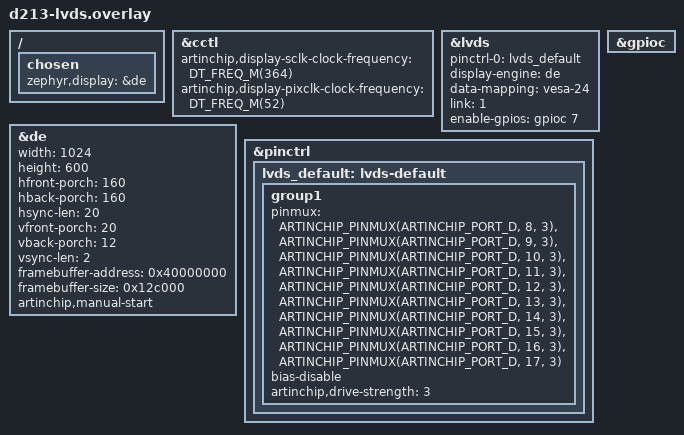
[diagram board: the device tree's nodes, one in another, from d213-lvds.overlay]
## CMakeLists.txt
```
# SPDX-FileCopyrightText: Copyright (c) 2026 UltraSemi
# SPDX-License-Identifier: Apache-2.0
cmake_minimum_required(VERSION 3.20.0)
find_package(Zephyr REQUIRED HINTS $ENV{ZEPHYR_BASE})
project(boot_shell)
target_sources(app PRIVATE src/main.c)
target_sources_ifdef(CONFIG_DISPLAY app PRIVATE src/display_test.c)
```

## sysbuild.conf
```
# SPDX-FileCopyrightText: Copyright (c) 2026 UltraSemi
# SPDX-License-Identifier: Apache-2.0
SB_CONFIG_BOOTLOADER_MCUBOOT=y
SB_CONFIG_MCUBOOT_MODE_RAM_LOAD=y
SB_CONFIG_BOOT_SIGNATURE_TYPE_ECDSA_P256=y
```

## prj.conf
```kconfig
# SPDX-FileCopyrightText: Copyright (c) 2026 UltraSemi
# SPDX-License-Identifier: Apache-2.0
CONFIG_SERIAL=y
CONFIG_CONSOLE=y
CONFIG_UART_CONSOLE=y
CONFIG_SHELL=y
CONFIG_SHELL_BACKEND_SERIAL=y
CONFIG_SHELL_BACKEND_SERIAL_INTERRUPT_DRIVEN=n
CONFIG_SHELL_BACKEND_SERIAL_API_POLLING=y
CONFIG_SHELL_BACKEND_SERIAL_RX_POLL_PERIOD=2
CONFIG_SHELL_BACKEND_SERIAL_RX_RING_BUFFER_SIZE=256
CONFIG_SHELL_PROMPT_UART="aic:~$ "
CONFIG_LOG=y
CONFIG_LOG_BACKEND_UART=n
CONFIG_SHELL_LOG_BACKEND=y
CONFIG_BOOT_BANNER=n
CONFIG_MAIN_STACK_SIZE=2048
```

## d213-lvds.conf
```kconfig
# SPDX-FileCopyrightText: Copyright (c) 2026 UltraSemi
# SPDX-License-Identifier: Apache-2.0
CONFIG_DISPLAY=y
CONFIG_GPIO=y
CONFIG_MAIN_STACK_SIZE=4096
CONFIG_MAIN_THREAD_PRIORITY=5
```

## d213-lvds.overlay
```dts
/*
 * SPDX-FileCopyrightText: Copyright (c) 2026 UltraSemi Technology Development Co., Ltd.
 * SPDX-License-Identifier: Apache-2.0
 *
 * D213 demo128 NAND: LubanLite origin/master f2ee295b1a09 LVDS defaults.
 */

#include <zephyr/dt-bindings/gpio/gpio.h>
#include <zephyr/dt-bindings/pinctrl/artinchip-pinctrl.h>

/ {
	chosen {
		zephyr,display = &de;
	};
};

&cctl {
	artinchip,display-sclk-clock-frequency = <DT_FREQ_M(364)>;
	artinchip,display-pixclk-clock-frequency = <DT_FREQ_M(52)>;
};

&lvds {
	pinctrl-0 = <&lvds_default>;
	pinctrl-names = "default";
	display-engine = <&de>;
	data-mapping = "vesa-24";
	link = <1>;
	enable-gpios = <&gpioc 7 GPIO_ACTIVE_HIGH>;
	status = "okay";
};

&de {
	width = <1024>;
	height = <600>;
	hfront-porch = <160>;
	hback-porch = <160>;
	hsync-len = <20>;
	vfront-porch = <20>;
	vback-porch = <12>;
	vsync-len = <2>;
	framebuffer-address = <0x40000000>;
	framebuffer-size = <0x12c000>;
	status = "okay";
	artinchip,manual-start;
};

&pinctrl {
	lvds_default: lvds-default {
		group1 {
			pinmux = <ARTINCHIP_PINMUX(ARTINCHIP_PORT_D, 8, 3)>,
				 <ARTINCHIP_PINMUX(ARTINCHIP_PORT_D, 9, 3)>,
				 <ARTINCHIP_PINMUX(ARTINCHIP_PORT_D, 10, 3)>,
				 <ARTINCHIP_PINMUX(ARTINCHIP_PORT_D, 11, 3)>,
				 <ARTINCHIP_PINMUX(ARTINCHIP_PORT_D, 12, 3)>,
				 <ARTINCHIP_PINMUX(ARTINCHIP_PORT_D, 13, 3)>,
				 <ARTINCHIP_PINMUX(ARTINCHIP_PORT_D, 14, 3)>,
				 <ARTINCHIP_PINMUX(ARTINCHIP_PORT_D, 15, 3)>,
				 <ARTINCHIP_PINMUX(ARTINCHIP_PORT_D, 16, 3)>,
				 <ARTINCHIP_PINMUX(ARTINCHIP_PORT_D, 17, 3)>;
			bias-disable;
			artinchip,drive-strength = <3>;
		};
	};
};

&gpioc {
	status = "okay";
};
```

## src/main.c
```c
/*
 * SPDX-FileCopyrightText: Copyright (c) 2026 UltraSemi
 * SPDX-License-Identifier: Apache-2.0
 */
#include <zephyr/kernel.h>
#include <zephyr/logging/log.h>

LOG_MODULE_REGISTER(boot_shell, LOG_LEVEL_INF);

#ifdef CONFIG_DISPLAY
int boot_display_test(void);
#endif

int main(void)
{
	LOG_INF("Zephyr boot test: %s", CONFIG_BOARD_TARGET);
#ifdef CONFIG_DISPLAY
	return boot_display_test();
#else
	LOG_INF("Type help to test the shell; display is not enabled in this image");
#endif
	return 0;
}
```

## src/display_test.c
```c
/*
 * SPDX-FileCopyrightText: Copyright (c) 2026 UltraSemi
 * SPDX-License-Identifier: Apache-2.0
 */
#include <zephyr/device.h>
#include <zephyr/drivers/display.h>
#include <zephyr/kernel.h>
#include <zephyr/logging/log.h>

LOG_MODULE_REGISTER(display_test, LOG_LEVEL_INF);

static uint16_t row[1024];
static const uint16_t colors[] = {0xffff, 0xffe0, 0x07ff, 0x07e0,
				0xf81f, 0xf800, 0x001f, 0x0000};

int boot_display_test(void)
{
	const struct device *display = DEVICE_DT_GET(DT_CHOSEN(zephyr_display));
	struct display_capabilities caps;
	struct display_buffer_descriptor desc = {0};
	uint16_t marker = 0;
	int ret;

	if (!device_is_ready(display)) {
		LOG_ERR("Display is not ready; shell remains available");
		return -ENODEV;
	}
	display_get_capabilities(display, &caps);
	if (caps.x_resolution == 0U || caps.x_resolution > ARRAY_SIZE(row) ||
	    caps.y_resolution == 0U) {
		return -ENOTSUP;
	}
	ret = display_set_pixel_format(display, PIXEL_FORMAT_RGB_565);
	if (ret != 0) {
		return ret;
	}
	desc.width = caps.x_resolution;
	desc.height = 1;
	desc.pitch = caps.x_resolution;
	desc.buf_size = caps.x_resolution * sizeof(row[0]);
	ret = display_blanking_off(display);
	if (ret != 0) {
		LOG_ERR("Display enable failed: %d", ret);
		return ret;
	}
	LOG_INF("LVDS test: %ux%u color bars with moving white marker; shell enabled",
		caps.x_resolution, caps.y_resolution);
	while (true) {
		for (uint16_t y = 0; y < caps.y_resolution; y++) {
			for (uint16_t x = 0; x < caps.x_resolution; x++) {
				bool border = x < 2U || x >= caps.x_resolution - 2U ||
					      y < 2U || y >= caps.y_resolution - 2U;

				row[x] = (border || x == marker) ? 0xffffU :
					 colors[x * ARRAY_SIZE(colors) / caps.x_resolution];
			}
			ret = display_write(display, 0, y, &desc, row);
			if (ret != 0) {
				LOG_ERR("Display write failed: %d", ret);
				return ret;
			}
		}
		marker = (marker + 16U) % caps.x_resolution;
		k_msleep(250);
	}
}
```
